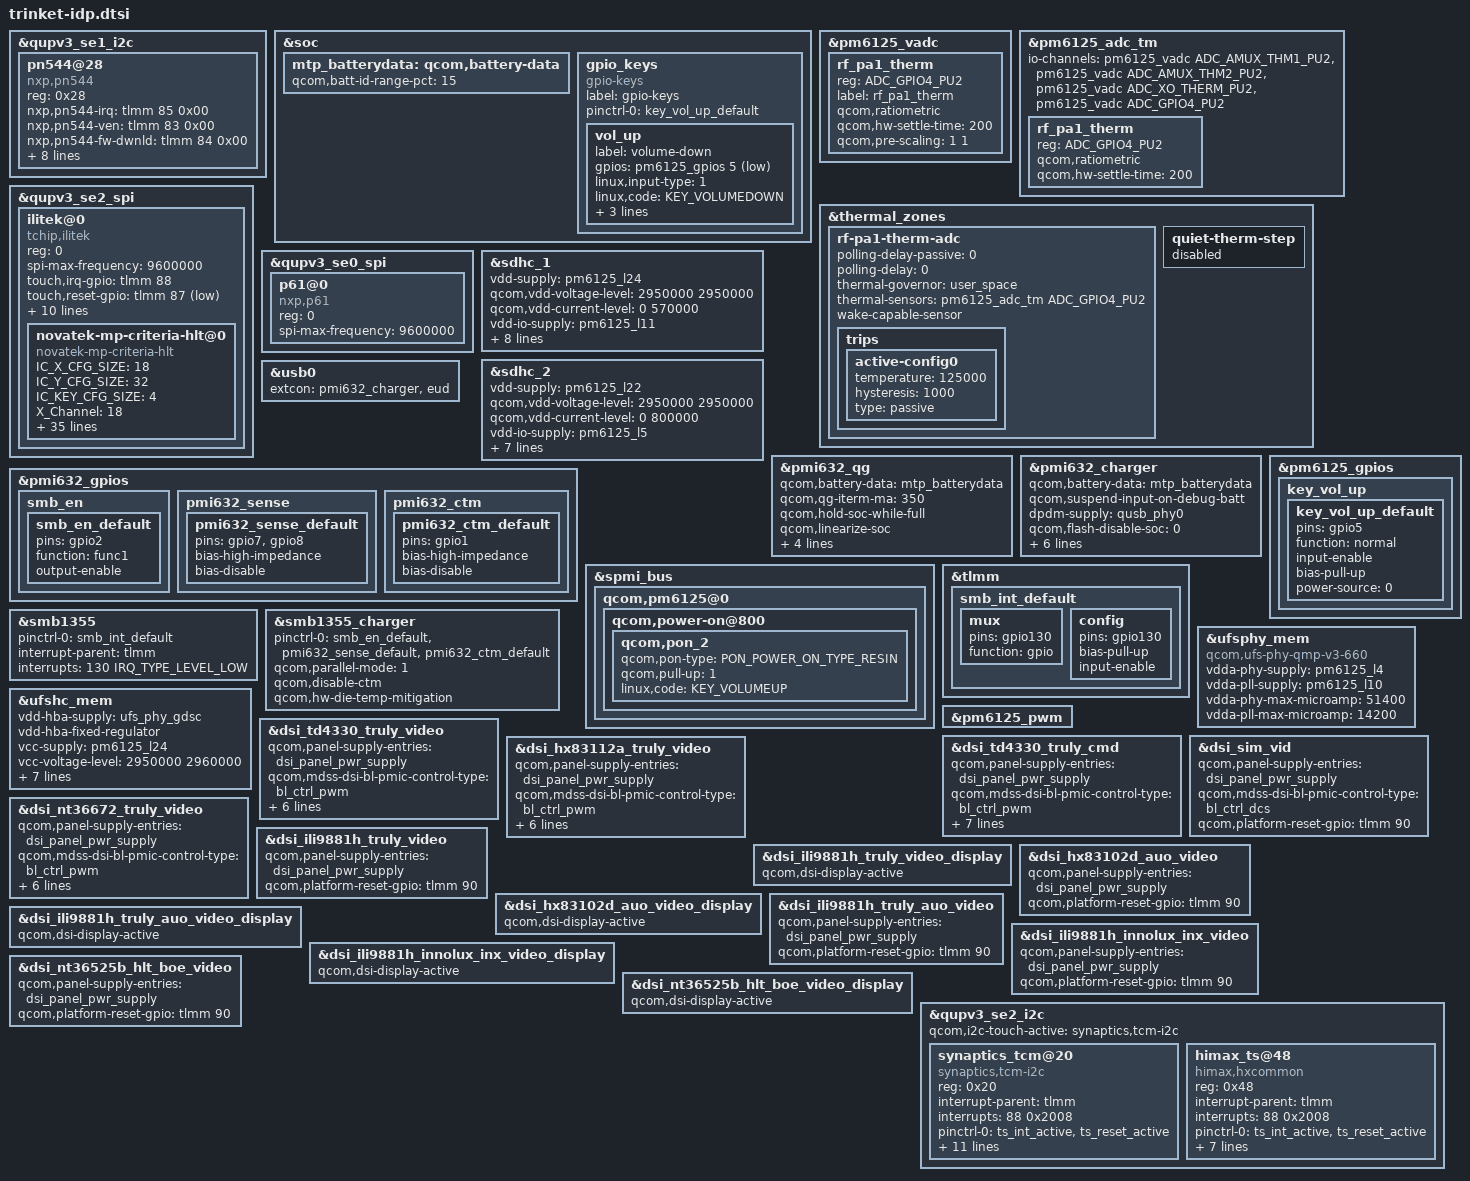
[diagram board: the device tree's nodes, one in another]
/*
 * Copyright (c) 2018-2019, The Linux Foundation. All rights reserved.
 *
 * This program is free software; you can redistribute it and/or modify
 * it under the terms of the GNU General Public License version 2 and
 * only version 2 as published by the Free Software Foundation.
 *
 * This program is distributed in the hope that it will be useful,
 * but WITHOUT ANY WARRANTY; without even the implied warranty of
 * MERCHANTABILITY or FITNESS FOR A PARTICULAR PURPOSE.  See the
 * GNU General Public License for more details.
 */
#include <dt-bindings/gpio/gpio.h>
#include <dt-bindings/input/input.h>
#include <dt-bindings/iio/qcom,spmi-vadc.h>
#include "trinket-thermal-overlay.dtsi"
#include "trinket-sde-display.dtsi"
#include <dt-bindings/clock/qcom,gcc-trinket.h>
#include "trinket-camera-sensor-idp.dtsi"
//Gong.Chen@ODM_WT.Bsp.Key.Function.1941873, 2019/04/10, Add for keyfunction
#include <dt-bindings/input/qcom,qpnp-power-on.h>

&qupv3_se1_i2c {
	status = "ok";
	#include "smb1355.dtsi"
};

&soc {
	mtp_batterydata: qcom,battery-data {
	//#ifndef ODM_WT_EDIT
	//Bin2.Zhang@ODM_WT.BSP.Charger.Basic.1941873, 20190416, Modify for battery temperature scale function
	//	qcom,batt-id-range-pct = <15>;
	//	#include "qg-batterydata-ascent-3450mah.dtsi"
	//	#include "qg-batterydata-mlp356477-2800mah.dtsi"
	//#else /* ODM_WT_EDIT */
		qcom,batt-id-range-pct = <15>;
		//#include "qg-batterydata-OPPO-DD003desay-ATL-4v4-4230mAh.dtsi"
		#include "qg-batterydata-OPPO-Brandon_ATL-4910mAh.dtsi"
	//#endif /* ODM_WT_EDIT */
	};

};

&pm6125_vadc {
	rf_pa1_therm {
		reg = <ADC_GPIO4_PU2>;
		label = "rf_pa1_therm";
		qcom,ratiometric;
		qcom,hw-settle-time = <200>;
		qcom,pre-scaling = <1 1>;
	};
};

&pm6125_adc_tm {
	io-channels = <&pm6125_vadc ADC_AMUX_THM1_PU2>,
			<&pm6125_vadc ADC_AMUX_THM2_PU2>,
			<&pm6125_vadc ADC_XO_THERM_PU2>,
			<&pm6125_vadc ADC_GPIO4_PU2>;

	rf_pa1_therm {
		reg = <ADC_GPIO4_PU2>;
		qcom,ratiometric;
		qcom,hw-settle-time = <200>;
	};
};

&thermal_zones {
	rf-pa1-therm-adc {
		polling-delay-passive = <0>;
		polling-delay = <0>;
		thermal-governor = "user_space";
		thermal-sensors = <&pm6125_adc_tm ADC_GPIO4_PU2>;
		wake-capable-sensor;
		trips {
			active-config0 {
				temperature = <125000>;
				hysteresis = <1000>;
				type = "passive";
			};
		};
	};

	quiet-therm-step {
		status = "disabled";
	};
};

&qupv3_se1_i2c {
	status = "ok";
/*Yuexiu.Wu@ODM_WT.WCN.NFC.Basic.1941873,2019/5/12,modify for use NXP NFC driver*/
	pn544@28 {
		compatible = "nxp,pn544";
		reg = <0x28>;
		nxp,pn544-irq = <&tlmm 85 0x00>;
		nxp,pn544-ven = <&tlmm 83 0x00>;
		nxp,pn544-fw-dwnld = <&tlmm 84 0x00>;
		nxp,pn544-clkreq = <&tlmm 95 0x00>;
		nxp,pn544-ese-pwr = <&tlmm 86 0x00>;
		interrupt-parent = <&tlmm>;
		interrupts = <85 0>;
		interrupt-names = "nfc_irq";
		pinctrl-names = "nfc_active", "nfc_suspend";
		pinctrl-0 = <&nfc_int_active &nfc_enable_active
				&nfc_clk_req_active>;
		pinctrl-1 = <&nfc_int_suspend &nfc_enable_suspend
				&nfc_clk_req_suspend>;
	};
};

&qupv3_se2_spi {
	status = "ok";
	ilitek@0 {
		compatible = "tchip,ilitek","novatek,NVT-ts-spi";
		reg = <0>; //Same as CS ID
		spi-max-frequency = <9600000>;	//4800000,9600000,15000000,19200000
		touch,irq-gpio = <&tlmm 88 0x00>;
		touch,reset-gpio = <&tlmm 87 0x2001>;
		pinctrl-names = "default", "suspend";
		pinctrl-0 = <&ts_int_active &ts_reset_active>;
		pinctrl-1 = <&ts_int_suspend &ts_reset_suspend>;
		vddio-supply = <&L9A>;
		lab-supply = <&lcdb_ldo_vreg>;
		ibb-supply = <&lcdb_ncp_vreg>;

		novatek,irq-gpio = <&tlmm 88 0>;
		novatek,reset-gpio = <&tlmm 87 0>;
		novatek,reset_global_gpio = <&tlmm 90 0>;
		/* 672A, 525B */
		novatek,swrst-n8-addr = <0x03F0FE>;
		status = "ok";

		/* MP */
		novatek,mp-support-dt;
		novatek-mp-criteria-hlt@0 {
			#address-cells = <1>;
			#size-cells = <0>;
			compatible = "novatek-mp-criteria-hlt";

			/* MP Config */
			IC_X_CFG_SIZE = <18>;
			IC_Y_CFG_SIZE = <32>;
			IC_KEY_CFG_SIZE = <4>;
			X_Channel = <18>;
			Y_Channel = <32>;
			AIN_X = <0 1 2 3 4 5 6 7 8 9 10 11 12 13 14 15 16 17>;
			AIN_Y = <0 1 2 3 4 5 6 7 8 9 10 11 12 13 14 15 16 17 18 19
								20 21 22 23 24 25 26 27 28 29 30 31>;
			AIN_KEY = <0 1 2 0xFF>;

			/* MP Criteria */
			PS_Config_Lmt_Short_Rawdata_P = <
				14008 14008 14008 14008 14008 14008 14008 14008 14008 14008 14008 14008 14008 14008 14008 14008 14008 14008
				14008 14008 14008 14008 14008 14008 14008 14008 14008 14008 14008 14008 14008 14008 14008 14008 14008 14008
				14008 14008 14008 14008 14008 14008 14008 14008 14008 14008 14008 14008 14008 14008 14008 14008 14008 14008
				14008 14008 14008 14008 14008 14008 14008 14008 14008 14008 14008 14008 14008 14008 14008 14008 14008 14008
				14008 14008 14008 14008 14008 14008 14008 14008 14008 14008 14008 14008 14008 14008 14008 14008 14008 14008
				14008 14008 14008 14008 14008 14008 14008 14008 14008 14008 14008 14008 14008 14008 14008 14008 14008 14008
				14008 14008 14008 14008 14008 14008 14008 14008 14008 14008 14008 14008 14008 14008 14008 14008 14008 14008
				14008 14008 14008 14008 14008 14008 14008 14008 14008 14008 14008 14008 14008 14008 14008 14008 14008 14008
				14008 14008 14008 14008 14008 14008 14008 14008 14008 14008 14008 14008 14008 14008 14008 14008 14008 14008
				14008 14008 14008 14008 14008 14008 14008 14008 14008 14008 14008 14008 14008 14008 14008 14008 14008 14008
				14008 14008 14008 14008 14008 14008 14008 14008 14008 14008 14008 14008 14008 14008 14008 14008 14008 14008
				14008 14008 14008 14008 14008 14008 14008 14008 14008 14008 14008 14008 14008 14008 14008 14008 14008 14008
				14008 14008 14008 14008 14008 14008 14008 14008 14008 14008 14008 14008 14008 14008 14008 14008 14008 14008
				14008 14008 14008 14008 14008 14008 14008 14008 14008 14008 14008 14008 14008 14008 14008 14008 14008 14008
				14008 14008 14008 14008 14008 14008 14008 14008 14008 14008 14008 14008 14008 14008 14008 14008 14008 14008
				14008 14008 14008 14008 14008 14008 14008 14008 14008 14008 14008 14008 14008 14008 14008 14008 14008 14008
				14008 14008 14008 14008 14008 14008 14008 14008 14008 14008 14008 14008 14008 14008 14008 14008 14008 14008
				14008 14008 14008 14008 14008 14008 14008 14008 14008 14008 14008 14008 14008 14008 14008 14008 14008 14008
				14008 14008 14008 14008 14008 14008 14008 14008 14008 14008 14008 14008 14008 14008 14008 14008 14008 14008
				14008 14008 14008 14008 14008 14008 14008 14008 14008 14008 14008 14008 14008 14008 14008 14008 14008 14008
				14008 14008 14008 14008 14008 14008 14008 14008 14008 14008 14008 14008 14008 14008 14008 14008 14008 14008
				14008 14008 14008 14008 14008 14008 14008 14008 14008 14008 14008 14008 14008 14008 14008 14008 14008 14008
				14008 14008 14008 14008 14008 14008 14008 14008 14008 14008 14008 14008 14008 14008 14008 14008 14008 14008
				14008 14008 14008 14008 14008 14008 14008 14008 14008 14008 14008 14008 14008 14008 14008 14008 14008 14008
				14008 14008 14008 14008 14008 14008 14008 14008 14008 14008 14008 14008 14008 14008 14008 14008 14008 14008
				14008 14008 14008 14008 14008 14008 14008 14008 14008 14008 14008 14008 14008 14008 14008 14008 14008 14008
				14008 14008 14008 14008 14008 14008 14008 14008 14008 14008 14008 14008 14008 14008 14008 14008 14008 14008
				14008 14008 14008 14008 14008 14008 14008 14008 14008 14008 14008 14008 14008 14008 14008 14008 14008 14008
				14008 14008 14008 14008 14008 14008 14008 14008 14008 14008 14008 14008 14008 14008 14008 14008 14008 14008
				14008 14008 14008 14008 14008 14008 14008 14008 14008 14008 14008 14008 14008 14008 14008 14008 14008 14008
				14008 14008 14008 14008 14008 14008 14008 14008 14008 14008 14008 14008 14008 14008 14008 14008 14008 14008
				14008 14008 14008 14008 14008 14008 14008 14008 14008 14008 14008 14008 14008 14008 14008 14008 14008 14008
				>;

			PS_Config_Lmt_Short_Rawdata_N = <
				11376 11376 11376 11376 11376 11376 11376 11376 11376 11376 11376 11376 11376 11376 11376 11376 11376 11376
				11376 11376 11376 11376 11376 11376 11376 11376 11376 11376 11376 11376 11376 11376 11376 11376 11376 11376
				11376 11376 11376 11376 11376 11376 11376 11376 11376 11376 11376 11376 11376 11376 11376 11376 11376 11376
				11376 11376 11376 11376 11376 11376 11376 11376 11376 11376 11376 11376 11376 11376 11376 11376 11376 11376
				11376 11376 11376 11376 11376 11376 11376 11376 11376 11376 11376 11376 11376 11376 11376 11376 11376 11376
				11376 11376 11376 11376 11376 11376 11376 11376 11376 11376 11376 11376 11376 11376 11376 11376 11376 11376
				11376 11376 11376 11376 11376 11376 11376 11376 11376 11376 11376 11376 11376 11376 11376 11376 11376 11376
				11376 11376 11376 11376 11376 11376 11376 11376 11376 11376 11376 11376 11376 11376 11376 11376 11376 11376
				11376 11376 11376 11376 11376 11376 11376 11376 11376 11376 11376 11376 11376 11376 11376 11376 11376 11376
				11376 11376 11376 11376 11376 11376 11376 11376 11376 11376 11376 11376 11376 11376 11376 11376 11376 11376
				11376 11376 11376 11376 11376 11376 11376 11376 11376 11376 11376 11376 11376 11376 11376 11376 11376 11376
				11376 11376 11376 11376 11376 11376 11376 11376 11376 11376 11376 11376 11376 11376 11376 11376 11376 11376
				11376 11376 11376 11376 11376 11376 11376 11376 11376 11376 11376 11376 11376 11376 11376 11376 11376 11376
				11376 11376 11376 11376 11376 11376 11376 11376 11376 11376 11376 11376 11376 11376 11376 11376 11376 11376
				11376 11376 11376 11376 11376 11376 11376 11376 11376 11376 11376 11376 11376 11376 11376 11376 11376 11376
				11376 11376 11376 11376 11376 11376 11376 11376 11376 11376 11376 11376 11376 11376 11376 11376 11376 11376
				11376 11376 11376 11376 11376 11376 11376 11376 11376 11376 11376 11376 11376 11376 11376 11376 11376 11376
				11376 11376 11376 11376 11376 11376 11376 11376 11376 11376 11376 11376 11376 11376 11376 11376 11376 11376
				11376 11376 11376 11376 11376 11376 11376 11376 11376 11376 11376 11376 11376 11376 11376 11376 11376 11376
				11376 11376 11376 11376 11376 11376 11376 11376 11376 11376 11376 11376 11376 11376 11376 11376 11376 11376
				11376 11376 11376 11376 11376 11376 11376 11376 11376 11376 11376 11376 11376 11376 11376 11376 11376 11376
				11376 11376 11376 11376 11376 11376 11376 11376 11376 11376 11376 11376 11376 11376 11376 11376 11376 11376
				11376 11376 11376 11376 11376 11376 11376 11376 11376 11376 11376 11376 11376 11376 11376 11376 11376 11376
				11376 11376 11376 11376 11376 11376 11376 11376 11376 11376 11376 11376 11376 11376 11376 11376 11376 11376
				11376 11376 11376 11376 11376 11376 11376 11376 11376 11376 11376 11376 11376 11376 11376 11376 11376 11376
				11376 11376 11376 11376 11376 11376 11376 11376 11376 11376 11376 11376 11376 11376 11376 11376 11376 11376
				11376 11376 11376 11376 11376 11376 11376 11376 11376 11376 11376 11376 11376 11376 11376 11376 11376 11376
				11376 11376 11376 11376 11376 11376 11376 11376 11376 11376 11376 11376 11376 11376 11376 11376 11376 11376
				11376 11376 11376 11376 11376 11376 11376 11376 11376 11376 11376 11376 11376 11376 11376 11376 11376 11376
				11376 11376 11376 11376 11376 11376 11376 11376 11376 11376 11376 11376 11376 11376 11376 11376 11376 11376
				11376 11376 11376 11376 11376 11376 11376 11376 11376 11376 11376 11376 11376 11376 11376 11376 11376 11376
				11376 11376 11376 11376 11376 11376 11376 11376 11376 11376 11376 11376 11376 11376 11376 11376 11376 11376
				>;

			PS_Config_Lmt_Open_Rawdata_P = <
				3120	3133	3130	3154	3185	3147	3129	3200	65535 65535 3103	3036	3067	3108	3151	3206	3227	3165
				2879	2899	2934	2996	3052	3040	3025	3008	2954	2910	2984	2998	3025	3039	3059	3075	3052	2982
				2961	2980	3017	3085	3151	3143	3122	3108	3033	2924	3005	3028	3049	3064	3080	3103	3078	3024
				2973	2980	3015	3085	3155	3148	3130	3115	3039	2969	3056	3077	3099	3116	3131	3154	3136	3087
				3000	3011	3045	3117	3189	3179	3158	3145	3063	2951	3038	3061	3082	3103	3116	3138	3124	3080
				2986	2993	3028	3101	3175	3183	3162	3150	3063	3011	3108	3130	3152	3173	3185	3207	3201	3155
				3082	3105	3133	3138	3136	3123	3126	3109	3067	3186	3218	3245	3241	3232	3148	3061	2997	2940
				3123	3143	3176	3183	3175	3169	3158	3148	3105	3218	3253	3271	3281	3283	3203	3113	3046	2990
				3126	3145	3185	3194	3185	3182	3161	3157	3109	3225	3263	3278	3298	3298	3220	3127	3064	3008
				3171	3189	3236	3242	3236	3234	3217	3200	3152	3276	3316	3341	3360	3367	3281	3193	3127	3071
				3208	3222	3271	3277	3264	3259	3239	3222	3183	3281	3318	3343	3365	3374	3306	3218	3151	3096
				3249	3263	3318	3326	3318	3311	3280	3264	3228	3327	3365	3389	3424	3432	3364	3271	3204	3148
				3246	3257	3339	3341	3337	3323	3298	3284	3253	3336	3371	3392	3425	3438	3372	3288	3206	3144
				3271	3297	3368	3382	3364	3357	3330	3318	3287	3382	3417	3438	3472	3481	3432	3348	3266	3201
				3313	3339	3407	3417	3403	3385	3368	3358	3320	3389	3431	3453	3473	3501	3451	3376	3294	3229
				3355	3386	3452	3472	3449	3439	3413	3402	3358	3446	3490	3515	3544	3561	3526	3448	3364	3297
				3371	3399	3467	3479	3467	3456	3434	3420	3376	3437	3483	3508	3536	3554	3521	3456	3372	3306
				3414	3444	3505	3518	3507	3494	3469	3456	3409	3469	3518	3544	3571	3592	3563	3501	3424	3357
				3445	3466	3532	3532	3530	3521	3501	3480	3434	3487	3547	3570	3603	3617	3595	3540	3472	3397
				3491	3516	3577	3588	3577	3563	3543	3521	3470	3515	3575	3600	3631	3649	3640	3582	3514	3438
				3508	3523	3584	3600	3588	3575	3557	3535	3483	3516	3582	3605	3637	3652	3649	3588	3526	3458
				3546	3557	3619	3641	3627	3614	3596	3574	3518	3553	3620	3644	3676	3691	3698	3642	3575	3509
				3592	3609	3654	3711	3708	3694	3672	3654	3591	3556	3628	3649	3682	3697	3719	3693	3642	3578
				3606	3621	3662	3712	3715	3701	3680	3663	3596	3616	3691	3715	3747	3761	3782	3770	3718	3655
				3651	3656	3697	3743	3752	3738	3719	3698	3634	3582	3655	3680	3707	3724	3743	3738	3690	3634
				3661	3663	3701	3743	3754	3742	3725	3705	3638	3638	3717	3742	3767	3785	3806	3808	3763	3708
				3516	3724	3752	3796	3809	3798	3802	3785	3717	3666	3743	3767	3768	3789	3806	3809	3774	3511
				3511	3722	3756	3787	3802	3789	3795	3775	3705	3712	3794	3817	3822	3840	3858	3876	3841	3564
				3554	3773	3799	3831	3847	3836	3837	3823	3747	3686	3770	3789	3796	3816	3834	3852	3826	3546
				3536	3756	3784	3809	3827	3817	3819	3805	3728	3739	3824	3845	3852	3872	3892	3920	3892	3603
				3599	3823	3845	3865	3883	3872	3875	3861	3785	3726	3813	3834	3843	3861	3879	3908	3890	3600
				3683	3743	3840	3859	3878	3865	3868	3852	3774	3771	3865	3887	3894	3914	3934	3962	3864	3747
				>;

			PS_Config_Lmt_Open_Rawdata_N = <
				1337	1342	1341	1351	1365	1348	1341	1371	(-65535) (-65535) 1330 1301 1314 1332 1350 1374 1383 1356
				1234	1242	1257	1284	1308	1303	1296	1289	1266	1247	1279	1285	1296	1302	1311	1318	1308	1278
				1269	1277	1293	1322	1350	1347	1338	1332	1300	1253	1288	1297	1306	1313	1320	1330	1319	1296
				1274	1277	1292	1322	1352	1349	1341	1335	1302	1272	1309	1318	1328	1335	1342	1351	1344	1323
				1285	1290	1305	1336	1366	1362	1353	1348	1312	1264	1302	1312	1321	1330	1335	1345	1339	1320
				1279	1282	1297	1329	1360	1364	1355	1350	1312	1290	1332	1341	1351	1360	1365	1374	1372	1352
				1321	1330	1342	1345	1344	1338	1339	1332	1314	1365	1379	1390	1389	1385	1349	1312	1284	1260
				1338	1347	1361	1364	1360	1358	1353	1349	1330	1379	1394	1402	1406	1407	1372	1334	1305	1281
				1339	1348	1365	1369	1365	1363	1354	1353	1332	1382	1398	1405	1413	1413	1380	1340	1313	1289
				1359	1366	1387	1389	1387	1386	1378	1371	1351	1404	1421	1432	1440	1443	1406	1368	1340	1316
				1375	1381	1402	1404	1399	1396	1388	1381	1364	1406	1422	1432	1442	1446	1417	1379	1350	1327
				1392	1398	1422	1425	1422	1419	1405	1399	1383	1426	1442	1452	1467	1471	1441	1402	1373	1349
				1391	1396	1431	1432	1430	1424	1413	1407	1394	1429	1444	1453	1468	1473	1445	1409	1374	1347
				1402	1413	1443	1449	1441	1438	1427	1422	1408	1449	1464	1473	1488	1492	1471	1435	1399	1372
				1420	1431	1460	1464	1458	1450	1443	1439	1423	1452	1470	1480	1488	1500	1479	1447	1411	1384
				1438	1451	1479	1488	1478	1474	1462	1458	1439	1477	1495	1506	1519	1526	1511	1477	1441	1413
				1444	1456	1486	1491	1486	1481	1471	1465	1447	1473	1492	1503	1515	1523	1509	1481	1445	1417
				1463	1476	1502	1507	1503	1497	1486	1481	1461	1486	1507	1519	1530	1539	1527	1500	1467	1438
				1476	1485	1513	1513	1513	1509	1500	1491	1471	1494	1520	1530	1544	1550	1540	1517	1488	1456
				1496	1507	1533	1537	1533	1527	1518	1509	1487	1506	1532	1543	1556	1564	1560	1535	1506	1473
				1503	1510	1536	1543	1537	1532	1524	1515	1492	1507	1535	1545	1558	1565	1564	1537	1511	1482
				1519	1524	1551	1560	1554	1549	1541	1531	1507	1522	1551	1561	1575	1582	1585	1561	1532	1504
				1539	1546	1566	1590	1589	1583	1573	1566	1539	1524	1555	1564	1578	1584	1594	1582	1561	1533
				1545	1552	1569	1591	1592	1586	1577	1570	1541	1549	1582	1592	1606	1612	1621	1615	1593	1566
				1564	1567	1584	1604	1608	1602	1594	1585	1557	1535	1566	1577	1588	1596	1604	1602	1581	1557
				1569	1570	1586	1604	1609	1603	1596	1588	1559	1559	1593	1603	1614	1622	1631	1632	1612	1589
				1507	1596	1608	1627	1632	1627	1629	1622	1593	1571	1604	1614	1615	1624	1631	1632	1617	1504
				1504	1595	1609	1623	1629	1624	1626	1618	1588	1591	1626	1636	1638	1645	1653	1661	1646	1527
				1523	1617	1628	1642	1648	1644	1644	1638	1606	1579	1615	1624	1627	1635	1643	1651	1639	1519
				1515	1609	1621	1632	1640	1636	1636	1630	1597	1602	1639	1648	1651	1659	1668	1680	1668	1544
				1542	1638	1648	1656	1664	1659	1660	1654	1622	1597	1634	1643	1647	1654	1662	1675	1667	1543
				1578	1604	1645	1654	1662	1656	1657	1651	1617	1616	1656	1666	1669	1677	1686	1698	1656	1606
				>;

			PS_Config_Lmt_FW_Rawdata_P = <
				1677	1682	1684	1675	1678	1675	1674	1674	65535 65535 1674 1675 1681 1681 1684 1684 1685 1682
				1675	1680	1678	1681	1678	1677	1678	1674	1671	1677	1681	1684	1688	1681	1681	1687	1675	1687
				1674	1687	1682	1681	1685	1681	1682	1687	1681	1678	1684	1681	1680	1685	1678	1678	1674	1684
				1689	1670	1680	1666	1668	1664	1667	1668	1677	1680	1680	1675	1684	1684	1685	1685	1681	1685
				1674	1696	1687	1681	1674	1673	1673	1684	1684	1687	1680	1682	1685	1680	1684	1691	1670	1689
				1684	1681	1682	1673	1671	1670	1667	1667	1691	1681	1673	1673	1681	1688	1691	1678	1680	1674
				1678	1681	1678	1681	1684	1689	1688	1675	1687	1684	1678	1682	1682	1681	1680	1678	1671	1685
				1678	1678	1667	1671	1681	1685	1678	1674	1684	1674	1677	1673	1674	1675	1689	1684	1685	1688
				1678	1689	1682	1682	1691	1689	1687	1687	1682	1671	1684	1685	1685	1677	1680	1680	1687	1687
				1685	1682	1689	1691	1682	1682	1682	1682	1685	1678	1671	1674	1678	1664	1682	1681	1678	1684
				1677	1677	1674	1668	1680	1675	1684	1670	1670	1682	1682	1687	1675	1675	1680	1687	1694	1680
				1681	1689	1675	1684	1682	1687	1675	1680	1680	1682	1671	1677	1675	1680	1677	1674	1677	1671
				1674	1678	1677	1687	1680	1673	1680	1687	1675	1681	1691	1695	1694	1681	1680	1678	1684	1678
				1673	1680	1681	1680	1682	1678	1682	1692	1685	1671	1673	1675	1684	1667	1674	1675	1687	1681
				1682	1698	1680	1675	1687	1684	1685	1687	1681	1678	1680	1681	1671	1682	1692	1675	1689	1682
				1677	1682	1678	1682	1685	1681	1684	1680	1680	1684	1682	1681	1685	1673	1684	1687	1673	1678
				1673	1681	1677	1688	1682	1674	1673	1673	1661	1680	1675	1673	1673	1667	1661	1685	1668	1668
				1684	1691	1667	1667	1667	1670	1670	1674	1680	1674	1680	1684	1680	1678	1681	1689	1678	1677
				1689	1694	1689	1691	1689	1680	1684	1687	1688	1675	1680	1687	1687	1677	1675	1677	1685	1678
				1688	1692	1688	1684	1681	1680	1681	1677	1674	1675	1675	1682	1678	1685	1688	1681	1684	1691
				1674	1677	1685	1671	1691	1688	1681	1692	1671	1687	1685	1682	1684	1678	1674	1678	1685	1680
				1684	1687	1682	1692	1677	1673	1670	1675	1684	1681	1681	1685	1688	1682	1682	1684	1685	1687
				1677	1674	1682	1673	1681	1694	1694	1674	1674	1684	1675	1678	1677	1680	1680	1678	1688	1675
				1687	1675	1680	1680	1681	1678	1678	1685	1684	1673	1685	1688	1688	1681	1691	1689	1682	1684
				1680	1687	1675	1673	1678	1678	1674	1671	1671	1687	1681	1677	1677	1673	1673	1680	1678	1681
				1671	1681	1688	1680	1677	1674	1678	1682	1691	1673	1682	1680	1678	1687	1674	1675	1677	1677
				1684	1673	1687	1685	1685	1681	1688	1681	1681	1680	1680	1684	1678	1684	1685	1687	1689	1670
				1698	1685	1685	1685	1675	1675	1674	1684	1670	1682	1685	1689	1689	1667	1680	1673	1688	1688
				1675	1680	1675	1671	1673	1684	1681	1681	1682	1677	1688	1687	1678	1684	1687	1675	1681	1675
				1687	1668	1674	1674	1681	1687	1674	1663	1677	1681	1682	1687	1681	1677	1675	1674	1691	1687
				1674	1674	1678	1680	1677	1681	1673	1668	1681	1695	1684	1680	1680	1675	1671	1678	1685	1689
				1675	1695	1684	1674	1680	1675	1684	1688	1677	1680	1685	1674	1678	1673	1680	1681	1671	1673
				>;

			PS_Config_Lmt_FW_Rawdata_N = <
				718 721 721 718 719 718 717 717 (-65535) (-65535) 717 718 720 720 721 721 722 721
				718 720 719 720 719 718 719 717 716 718 720 721 723 720 720 723 718 723
				717 723 721 720 722 720 721 723 720 719 721 720 720 722 719 719 717 721
				724 715 720 714 715 713 714 715 718 720 720 718 721 721 722 722 720 722
				717 727 723 720 717 717 717 721 721 723 720 721 722 720 721 724 715 724
				721 720 721 717 716 715 714 714 724 720 717 717 720 723 724 719 720 717
				719 720 719 720 721 724 723 718 723 721 719 721 721 720 720 719 716 722
				719 719 714 716 720 722 719 717 721 717 718 717 717 718 724 721 722 723
				719 724 721 721 724 724 723 723 721 716 721 722 722 718 720 720 723 723
				722 721 724 724 721 721 721 721 722 719 716 717 719 713 721 720 719 721
				718 718 717 715 720 718 721 715 715 721 721 723 718 718 720 723 726 720
				720 724 718 721 721 723 718 720 720 721 716 718 718 720 718 717 718 716
				717 719 718 723 720 717 720 723 718 720 724 726 726 720 720 719 721 719
				717 720 720 720 721 719 721 725 722 716 717 718 721 714 717 718 723 720
				721 727 720 718 723 721 722 723 720 719 720 720 716 721 725 718 724 721
				718 721 719 721 722 720 721 720 720 721 721 720 722 717 721 723 717 719
				717 720 718 723 721 717 717 717 712 720 718 717 717 714 712 722 715 715
				721 724 714 714 714 715 715 717 720 717 720 721 720 719 720 724 719 718
				724 726 724 724 724 720 721 723 723 718 720 723 723 718 718 718 722 719
				723 725 723 721 720 720 720 718 717 718 718 721 719 722 723 720 721 724
				717 718 722 716 724 723 720 725 716 723 722 721 721 719 717 719 722 720
				721 723 721 725 718 717 715 718 721 720 720 722 723 721 721 721 722 723
				718 717 721 717 720 726 726 717 717 721 718 719 718 720 720 719 723 718
				723 718 720 720 720 719 719 722 721 717 722 723 723 720 724 724 721 721
				720 723 718 717 719 719 717 716 716 723 720 718 718 717 717 720 719 720
				716 720 723 720 718 717 719 721 724 717 721 720 719 723 717 718 718 718
				721 717 723 722 722 720 723 720 720 720 720 721 719 721 722 723 724 715
				727 722 722 722 718 718 717 721 715 721 722 724 724 714 720 717 723 723
				718 720 718 716 717 721 720 720 721 718 723 723 719 721 723 718 720 718
				723 715 717 717 720 723 717 712 718 720 721 723 720 718 718 717 724 723
				717 717 719 720 718 720 717 715 720 726 721 720 720 718 716 719 722 724
				718 726 721 717 720 718 721 723 718 720 722 717 719 717 720 720 716 717
				>;

			PS_Config_Lmt_FW_CC_P = <
				100 99 99 100 100 100 102 102 65535 65535 103 103 102 102 102 102 102 102
				103 100 100 100 100 100 100 100 103 107 104 104 104 104 104 104 106 107
				104 102 102 102 102 102 102 102 106 107 103 103 103 103 103 104 104 107
				103 102 100 102 102 102 102 102 104 109 106 106 106 106 106 106 107 109
				104 103 102 103 103 103 103 103 107 107 104 104 104 104 104 104 106 107
				104 102 102 102 103 103 103 103 107 110 107 107 107 106 106 106 107 110
				106 104 103 103 103 103 103 103 107 111 107 107 107 107 106 106 106 109
				109 106 106 106 106 104 106 106 109 113 110 110 110 109 109 109 109 110
				106 104 104 104 103 103 103 104 107 111 107 107 107 107 107 106 106 109
				109 106 106 106 106 106 106 106 109 113 110 110 110 110 109 109 109 111
				107 104 104 104 103 103 104 104 107 110 107 107 107 107 107 106 106 109
				109 106 106 106 106 106 106 106 109 113 110 110 110 110 110 109 109 111
				107 104 104 104 103 103 103 104 107 111 107 107 107 107 107 106 106 109
				109 106 106 106 106 106 106 106 110 114 110 110 110 110 110 109 110 111
				107 104 104 104 103 103 103 104 107 110 107 107 107 107 107 106 107 109
				109 106 106 106 106 106 106 106 109 113 110 110 110 110 109 109 109 111
				107 104 104 104 104 103 104 104 107 111 107 107 107 107 107 107 107 110
				109 107 106 107 106 106 106 106 110 113 110 110 110 110 110 110 110 113
				107 104 104 104 103 103 103 104 107 111 107 107 107 107 107 107 107 110
				110 107 106 106 106 106 106 106 109 113 110 110 110 110 110 110 110 113
				109 106 104 106 104 104 104 104 107 111 107 107 107 107 107 107 109 110
				110 107 107 107 107 106 107 107 110 113 110 110 110 110 110 110 110 113
				107 106 104 104 104 104 104 104 107 109 106 106 106 106 106 106 107 109
				106 103 103 103 103 103 103 103 106 111 107 107 107 107 107 107 109 111
				107 106 104 104 104 104 104 104 107 110 107 107 106 106 106 106 107 110
				107 104 103 103 103 103 103 103 106 111 109 109 109 107 109 109 109 111
				106 106 104 104 104 104 104 104 107 110 106 106 106 106 106 106 107 107
				104 103 103 103 103 103 103 103 106 111 109 109 109 107 107 109 109 109
				106 106 104 104 104 104 104 104 107 110 107 107 107 106 106 106 107 107
				104 104 103 103 103 103 103 103 107 111 109 109 109 109 109 109 109 110
				106 106 104 104 104 104 104 104 109 110 107 107 107 106 106 106 107 107
				104 103 103 103 103 103 103 103 107 113 109 109 109 107 107 109 109 110
				>;

			PS_Config_Lmt_FW_CC_N = <
				45 44 44 45 45 45 45 45 (-65535) (-65535) 46 46 45 45 45 45 45 45
				46 45 45 45 45 45 45 45 46 48 47 47 47 47 47 47 47 48
				47 45 45 45 45 45 45 45 47 48 46 46 46 46 46 47 47 48
				46 45 45 45 45 45 45 45 47 48 47 47 47 47 47 47 48 48
				47 46 45 46 46 46 46 46 48 48 47 47 47 47 47 47 47 48
				47 45 45 45 46 46 46 46 48 49 48 48 48 47 47 47 48 49
				47 47 46 46 46 46 46 46 48 50 48 48 48 48 47 47 47 48
				48 47 47 47 47 47 47 47 48 50 49 49 49 48 48 48 48 49
				47 47 47 47 46 46 46 47 48 50 48 48 48 48 48 47 47 48
				48 47 47 47 47 47 47 47 48 50 49 49 49 49 48 48 48 50
				48 47 47 47 46 46 47 47 48 49 48 48 48 48 48 47 47 48
				48 47 47 47 47 47 47 47 48 50 49 49 49 49 49 48 48 50
				48 47 47 47 46 46 46 47 48 50 48 48 48 48 48 47 47 48
				48 47 47 47 47 47 47 47 49 51 49 49 49 49 49 48 49 50
				48 47 47 47 46 46 46 47 48 49 48 48 48 48 48 47 48 48
				48 47 47 47 47 47 47 47 48 50 49 49 49 49 48 48 48 50
				48 47 47 47 47 46 47 47 48 50 48 48 48 48 48 48 48 49
				48 48 47 48 47 47 47 47 49 50 49 49 49 49 49 49 49 50
				48 47 47 47 46 46 46 47 48 50 48 48 48 48 48 48 48 49
				49 48 47 47 47 47 47 47 48 50 49 49 49 49 49 49 49 50
				48 47 47 47 47 47 47 47 48 50 48 48 48 48 48 48 48 49
				49 48 48 48 48 47 48 48 49 50 49 49 49 49 49 49 49 50
				48 47 47 47 47 47 47 47 48 48 47 47 47 47 47 47 48 48
				47 46 46 46 46 46 46 46 47 50 48 48 48 48 48 48 48 50
				48 47 47 47 47 47 47 47 48 49 48 48 47 47 47 47 48 49
				48 47 46 46 46 46 46 46 47 50 48 48 48 48 48 48 48 50
				47 47 47 47 47 47 47 47 48 49 47 47 47 47 47 47 48 48
				47 46 46 46 46 46 46 46 47 50 48 48 48 48 48 48 48 48
				47 47 47 47 47 47 47 47 48 49 48 48 48 47 47 47 48 48
				47 47 46 46 46 46 46 46 48 50 48 48 48 48 48 48 48 49
				47 47 47 47 47 47 47 47 48 49 48 48 48 47 47 47 48 48
				47 46 46 46 46 46 46 46 48 50 48 48 48 48 48 48 48 49
				>;

			PS_Config_Lmt_FW_Diff_P = <
				50 50 50 50 50 50 50 50 65535 65535 50 50 50 50 50 50 50 50
				50 50 50 50 50 50 50 50 50 50 50 50 50 50 50 50 50 50
				50 50 50 50 50 50 50 50 50 50 50 50 50 50 50 50 50 50
				50 50 50 50 50 50 50 50 50 50 50 50 50 50 50 50 50 50
				50 50 50 50 50 50 50 50 50 50 50 50 50 50 50 50 50 50
				50 50 50 50 50 50 50 50 50 50 50 50 50 50 50 50 50 50
				50 50 50 50 50 50 50 50 50 50 50 50 50 50 50 50 50 50
				50 50 50 50 50 50 50 50 50 50 50 50 50 50 50 50 50 50
				50 50 50 50 50 50 50 50 50 50 50 50 50 50 50 50 50 50
				50 50 50 50 50 50 50 50 50 50 50 50 50 50 50 50 50 50
				50 50 50 50 50 50 50 50 50 50 50 50 50 50 50 50 50 50
				50 50 50 50 50 50 50 50 50 50 50 50 50 50 50 50 50 50
				50 50 50 50 50 50 50 50 50 50 50 50 50 50 50 50 50 50
				50 50 50 50 50 50 50 50 50 50 50 50 50 50 50 50 50 50
				50 50 50 50 50 50 50 50 50 50 50 50 50 50 50 50 50 50
				50 50 50 50 50 50 50 50 50 50 50 50 50 50 50 50 50 50
				50 50 50 50 50 50 50 50 50 50 50 50 50 50 50 50 50 50
				50 50 50 50 50 50 50 50 50 50 50 50 50 50 50 50 50 50
				50 50 50 50 50 50 50 50 50 50 50 50 50 50 50 50 50 50
				50 50 50 50 50 50 50 50 50 50 50 50 50 50 50 50 50 50
				50 50 50 50 50 50 50 50 50 50 50 50 50 50 50 50 50 50
				50 50 50 50 50 50 50 50 50 50 50 50 50 50 50 50 50 50
				50 50 50 50 50 50 50 50 50 50 50 50 50 50 50 50 50 50
				50 50 50 50 50 50 50 50 50 50 50 50 50 50 50 50 50 50
				50 50 50 50 50 50 50 50 50 50 50 50 50 50 50 50 50 50
				50 50 50 50 50 50 50 50 50 50 50 50 50 50 50 50 50 50
				50 50 50 50 50 50 50 50 50 50 50 50 50 50 50 50 50 50
				50 50 50 50 50 50 50 50 50 50 50 50 50 50 50 50 50 50
				50 50 50 50 50 50 50 50 50 50 50 50 50 50 50 50 50 50
				50 50 50 50 50 50 50 50 50 50 50 50 50 50 50 50 50 50
				50 50 50 50 50 50 50 50 50 50 50 50 50 50 50 50 50 50
				50 50 50 50 50 50 50 50 50 50 50 50 50 50 50 50 50 50
				>;

			PS_Config_Lmt_FW_Diff_N = <
				(-50) (-50) (-50) (-50) (-50) (-50) (-50) (-50) (-65535) (-65535) (-50) (-50) (-50) (-50) (-50) (-50) (-50) (-50)
				(-50) (-50) (-50) (-50) (-50) (-50) (-50) (-50) (-50) (-50) (-50) (-50) (-50) (-50) (-50) (-50) (-50) (-50)
				(-50) (-50) (-50) (-50) (-50) (-50) (-50) (-50) (-50) (-50) (-50) (-50) (-50) (-50) (-50) (-50) (-50) (-50)
				(-50) (-50) (-50) (-50) (-50) (-50) (-50) (-50) (-50) (-50) (-50) (-50) (-50) (-50) (-50) (-50) (-50) (-50)
				(-50) (-50) (-50) (-50) (-50) (-50) (-50) (-50) (-50) (-50) (-50) (-50) (-50) (-50) (-50) (-50) (-50) (-50)
				(-50) (-50) (-50) (-50) (-50) (-50) (-50) (-50) (-50) (-50) (-50) (-50) (-50) (-50) (-50) (-50) (-50) (-50)
				(-50) (-50) (-50) (-50) (-50) (-50) (-50) (-50) (-50) (-50) (-50) (-50) (-50) (-50) (-50) (-50) (-50) (-50)
				(-50) (-50) (-50) (-50) (-50) (-50) (-50) (-50) (-50) (-50) (-50) (-50) (-50) (-50) (-50) (-50) (-50) (-50)
				(-50) (-50) (-50) (-50) (-50) (-50) (-50) (-50) (-50) (-50) (-50) (-50) (-50) (-50) (-50) (-50) (-50) (-50)
				(-50) (-50) (-50) (-50) (-50) (-50) (-50) (-50) (-50) (-50) (-50) (-50) (-50) (-50) (-50) (-50) (-50) (-50)
				(-50) (-50) (-50) (-50) (-50) (-50) (-50) (-50) (-50) (-50) (-50) (-50) (-50) (-50) (-50) (-50) (-50) (-50)
				(-50) (-50) (-50) (-50) (-50) (-50) (-50) (-50) (-50) (-50) (-50) (-50) (-50) (-50) (-50) (-50) (-50) (-50)
				(-50) (-50) (-50) (-50) (-50) (-50) (-50) (-50) (-50) (-50) (-50) (-50) (-50) (-50) (-50) (-50) (-50) (-50)
				(-50) (-50) (-50) (-50) (-50) (-50) (-50) (-50) (-50) (-50) (-50) (-50) (-50) (-50) (-50) (-50) (-50) (-50)
				(-50) (-50) (-50) (-50) (-50) (-50) (-50) (-50) (-50) (-50) (-50) (-50) (-50) (-50) (-50) (-50) (-50) (-50)
				(-50) (-50) (-50) (-50) (-50) (-50) (-50) (-50) (-50) (-50) (-50) (-50) (-50) (-50) (-50) (-50) (-50) (-50)
				(-50) (-50) (-50) (-50) (-50) (-50) (-50) (-50) (-50) (-50) (-50) (-50) (-50) (-50) (-50) (-50) (-50) (-50)
				(-50) (-50) (-50) (-50) (-50) (-50) (-50) (-50) (-50) (-50) (-50) (-50) (-50) (-50) (-50) (-50) (-50) (-50)
				(-50) (-50) (-50) (-50) (-50) (-50) (-50) (-50) (-50) (-50) (-50) (-50) (-50) (-50) (-50) (-50) (-50) (-50)
				(-50) (-50) (-50) (-50) (-50) (-50) (-50) (-50) (-50) (-50) (-50) (-50) (-50) (-50) (-50) (-50) (-50) (-50)
				(-50) (-50) (-50) (-50) (-50) (-50) (-50) (-50) (-50) (-50) (-50) (-50) (-50) (-50) (-50) (-50) (-50) (-50)
				(-50) (-50) (-50) (-50) (-50) (-50) (-50) (-50) (-50) (-50) (-50) (-50) (-50) (-50) (-50) (-50) (-50) (-50)
				(-50) (-50) (-50) (-50) (-50) (-50) (-50) (-50) (-50) (-50) (-50) (-50) (-50) (-50) (-50) (-50) (-50) (-50)
				(-50) (-50) (-50) (-50) (-50) (-50) (-50) (-50) (-50) (-50) (-50) (-50) (-50) (-50) (-50) (-50) (-50) (-50)
				(-50) (-50) (-50) (-50) (-50) (-50) (-50) (-50) (-50) (-50) (-50) (-50) (-50) (-50) (-50) (-50) (-50) (-50)
				(-50) (-50) (-50) (-50) (-50) (-50) (-50) (-50) (-50) (-50) (-50) (-50) (-50) (-50) (-50) (-50) (-50) (-50)
				(-50) (-50) (-50) (-50) (-50) (-50) (-50) (-50) (-50) (-50) (-50) (-50) (-50) (-50) (-50) (-50) (-50) (-50)
				(-50) (-50) (-50) (-50) (-50) (-50) (-50) (-50) (-50) (-50) (-50) (-50) (-50) (-50) (-50) (-50) (-50) (-50)
				(-50) (-50) (-50) (-50) (-50) (-50) (-50) (-50) (-50) (-50) (-50) (-50) (-50) (-50) (-50) (-50) (-50) (-50)
				(-50) (-50) (-50) (-50) (-50) (-50) (-50) (-50) (-50) (-50) (-50) (-50) (-50) (-50) (-50) (-50) (-50) (-50)
				(-50) (-50) (-50) (-50) (-50) (-50) (-50) (-50) (-50) (-50) (-50) (-50) (-50) (-50) (-50) (-50) (-50) (-50)
				(-50) (-50) (-50) (-50) (-50) (-50) (-50) (-50) (-50) (-50) (-50) (-50) (-50) (-50) (-50) (-50) (-50) (-50)
				>;

			PS_Config_Diff_Test_Frame = <50>;

			PS_Config_Lmt_LPWG_Rawdata_P = <
				1689	1689	1696	1694	1677	1680	1674	1670	65535 65535	1689	1695	1685	1687	1692	1692	1691	1685
				1692	1682	1685	1677	1674	1681	1678	1673	1678	1684	1675	1673	1674	1678	1673	1685	1691	1680
				1689	1684	1677	1680	1688	1684	1681	1688	1698	1685	1680	1687	1689	1680	1681	1680	1674	1680
				1691	1703	1705	1681	1674	1675	1675	1675	1677	1689	1691	1691	1689	1695	1695	1691	1685	1688
				1687	1688	1681	1689	1691	1694	1699	1687	1695	1685	1685	1684	1684	1684	1680	1673	1696	1687
				1694	1685	1692	1687	1691	1691	1681	1689	1677	1689	1682	1681	1678	1680	1673	1678	1681	1687
				1681	1687	1682	1687	1675	1680	1682	1688	1685	1677	1680	1680	1681	1689	1677	1682	1678	1687
				1684	1687	1681	1691	1674	1680	1680	1687	1681	1678	1685	1684	1687	1685	1682	1675	1684	1687
				1684	1688	1684	1685	1692	1684	1687	1689	1691	1682	1678	1673	1671	1685	1684	1684	1684	1682
				1687	1692	1681	1685	1682	1682	1677	1678	1689	1666	1677	1666	1667	1691	1688	1687	1691	1687
				1680	1670	1675	1678	1688	1685	1687	1684	1678	1682	1678	1671	1677	1680	1692	1680	1694	1684
				1688	1671	1682	1681	1692	1685	1694	1685	1674	1663	1681	1678	1680	1684	1684	1684	1688	1694
				1687	1684	1684	1680	1684	1678	1684	1680	1677	1681	1685	1681	1677	1671	1688	1682	1685	1684
				1677	1688	1678	1688	1677	1684	1670	1682	1685	1675	1674	1675	1677	1682	1685	1681	1674	1675
				1681	1684	1687	1681	1674	1680	1687	1681	1685	1674	1673	1675	1685	1688	1675	1681	1684	1678
				1687	1684	1687	1688	1684	1681	1687	1682	1684	1677	1670	1671	1670	1682	1688	1673	1692	1682
				1685	1684	1680	1685	1674	1675	1681	1687	1677	1673	1674	1667	1661	1681	1687	1689	1675	1684
				1688	1685	1691	1680	1689	1681	1682	1680	1685	1688	1689	1692	1682	1687	1692	1682	1684	1689
				1673	1689	1677	1674	1677	1671	1675	1675	1682	1678	1682	1678	1677	1684	1684	1682	1684	1680
				1681	1682	1689	1689	1682	1681	1678	1681	1696	1689	1688	1684	1680	1687	1695	1680	1689	1680
				1681	1681	1688	1691	1677	1682	1684	1681	1691	1682	1678	1680	1681	1682	1685	1678	1677	1682
				1673	1680	1663	1680	1661	1671	1671	1667	1666	1688	1688	1682	1678	1681	1684	1681	1667	1695
				1675	1675	1684	1688	1682	1685	1687	1687	1687	1680	1682	1685	1677	1678	1678	1682	1666	1685
				1687	1692	1674	1678	1677	1682	1682	1681	1675	1691	1681	1685	1677	1685	1677	1681	1684	1685
				1675	1684	1666	1671	1681	1695	1691	1684	1677	1671	1668	1671	1666	1694	1674	1674	1675	1675
				1687	1681	1682	1684	1675	1675	1671	1678	1668	1673	1684	1681	1684	1685	1692	1675	1678	1684
				1682	1688	1684	1691	1677	1680	1681	1684	1689	1677	1677	1677	1682	1675	1678	1687	1685	1678
				1691	1675	1678	1677	1684	1680	1682	1681	1675	1680	1673	1673	1671	1682	1671	1674	1675	1694
				1675	1682	1675	1678	1691	1698	1687	1685	1688	1677	1681	1685	1682	1680	1675	1675	1688	1675
				1689	1680	1678	1680	1687	1694	1689	1682	1671	1682	1689	1691	1685	1663	1674	1674	1694	1684
				1680	1671	1689	1688	1692	1684	1698	1675	1661	1688	1681	1671	1674	1673	1668	1667	1678	1699
				1677	1688	1684	1688	1675	1685	1687	1688	1674	1680	1674	1674	1685	1682	1681	1680	1685	1673
				>;

			PS_Config_Lmt_LPWG_Rawdata_N = <
				724 724 727 726 718 720 717 715 (-65535) (-65535) 724 726 722 723 725 725 724 722
				725 721 722 718 717 720 719 717 719 721 718 717 717 719 717 722 724 720
				724 721 718 720 723 721 720 723 727 722 720 723 724 720 720 720 717 720
				724 730 730 720 717 718 718 718 718 724 724 724 724 726 726 724 722 723
				723 723 720 724 724 726 728 723 726 722 722 721 721 721 720 717 727 723
				726 722 725 723 724 724 720 724 718 724 721 720 719 720 717 719 720 723
				720 723 721 723 718 720 721 723 722 718 720 720 720 724 718 721 719 723
				721 723 720 724 717 720 720 723 720 719 722 721 723 722 721 718 721 723
				721 723 721 722 725 721 723 724 724 721 719 717 716 722 721 721 721 721
				723 725 720 722 721 721 718 719 724 714 718 714 714 724 723 723 724 723
				720 715 718 719 723 722 723 721 719 721 719 716 718 720 725 720 726 721
				723 716 721 720 725 722 726 722 717 712 720 719 720 721 721 721 723 726
				723 721 721 720 721 719 721 720 718 720 722 720 718 716 723 721 722 721
				718 723 719 723 718 721 715 721 722 718 717 718 718 721 722 720 717 718
				720 721 723 720 717 720 723 720 722 717 717 718 722 723 718 720 721 719
				723 721 723 723 721 720 723 721 721 718 715 716 715 721 723 717 725 721
				722 721 720 722 717 718 720 723 718 717 717 714 712 720 723 724 718 721
				723 722 724 720 724 720 721 720 722 723 724 725 721 723 725 721 721 724
				717 724 718 717 718 716 718 718 721 719 721 719 718 721 721 721 721 720
				720 721 724 724 721 720 719 720 727 724 723 721 720 723 726 720 724 720
				720 720 723 724 718 721 721 720 724 721 719 720 720 721 722 719 718 721
				717 720 712 720 712 716 716 714 714 723 723 721 719 720 721 720 714 726
				718 718 721 723 721 722 723 723 723 720 721 722 718 719 719 721 714 722
				723 725 717 719 718 721 721 720 718 724 720 722 718 722 718 720 721 722
				718 721 714 716 720 726 724 721 718 716 715 716 714 726 717 717 718 718
				723 720 721 721 718 718 716 719 715 717 721 720 721 722 725 718 719 721
				721 723 721 724 718 720 720 721 724 718 718 718 721 718 719 723 722 719
				724 718 719 718 721 720 721 720 718 720 717 717 716 721 716 717 718 726
				718 721 718 719 724 727 723 722 723 718 720 722 721 720 718 718 723 718
				724 720 719 720 723 726 724 721 716 721 724 724 722 712 717 717 726 721
				720 716 724 723 725 721 727 718 712 723 720 716 717 717 715 714 719 728
				718 723 721 723 718 722 723 723 717 720 717 717 722 721 720 720 722 717
				>;

			PS_Config_Lmt_LPWG_Diff_P = <
				60 60 60 60 60 60 60 60 65535 65535 60 60 60 60 60 60 60 60
				60 60 60 60 60 60 60 60 60 60 60 60 60 60 60 60 60 60
				60 60 60 60 60 60 60 60 60 60 60 60 60 60 60 60 60 60
				60 60 60 60 60 60 60 60 60 60 60 60 60 60 60 60 60 60
				60 60 60 60 60 60 60 60 60 60 60 60 60 60 60 60 60 60
				60 60 60 60 60 60 60 60 60 60 60 60 60 60 60 60 60 60
				60 60 60 60 60 60 60 60 60 60 60 60 60 60 60 60 60 60
				60 60 60 60 60 60 60 60 60 60 60 60 60 60 60 60 60 60
				60 60 60 60 60 60 60 60 60 60 60 60 60 60 60 60 60 60
				60 60 60 60 60 60 60 60 60 60 60 60 60 60 60 60 60 60
				60 60 60 60 60 60 60 60 60 60 60 60 60 60 60 60 60 60
				60 60 60 60 60 60 60 60 60 60 60 60 60 60 60 60 60 60
				60 60 60 60 60 60 60 60 60 60 60 60 60 60 60 60 60 60
				60 60 60 60 60 60 60 60 60 60 60 60 60 60 60 60 60 60
				60 60 60 60 60 60 60 60 60 60 60 60 60 60 60 60 60 60
				60 60 60 60 60 60 60 60 60 60 60 60 60 60 60 60 60 60
				60 60 60 60 60 60 60 60 60 60 60 60 60 60 60 60 60 60
				60 60 60 60 60 60 60 60 60 60 60 60 60 60 60 60 60 60
				60 60 60 60 60 60 60 60 60 60 60 60 60 60 60 60 60 60
				60 60 60 60 60 60 60 60 60 60 60 60 60 60 60 60 60 60
				60 60 60 60 60 60 60 60 60 60 60 60 60 60 60 60 60 60
				60 60 60 60 60 60 60 60 60 60 60 60 60 60 60 60 60 60
				60 60 60 60 60 60 60 60 60 60 60 60 60 60 60 60 60 60
				60 60 60 60 60 60 60 60 60 60 60 60 60 60 60 60 60 60
				60 60 60 60 60 60 60 60 60 60 60 60 60 60 60 60 60 60
				60 60 60 60 60 60 60 60 60 60 60 60 60 60 60 60 60 60
				60 60 60 60 60 60 60 60 60 60 60 60 60 60 60 60 60 60
				60 60 60 60 60 60 60 60 60 60 60 60 60 60 60 60 60 60
				60 60 60 60 60 60 60 60 60 60 60 60 60 60 60 60 60 60
				60 60 60 60 60 60 60 60 60 60 60 60 60 60 60 60 60 60
				60 60 60 60 60 60 60 60 60 60 60 60 60 60 60 60 60 60
				60 60 60 60 60 60 60 60 60 60 60 60 60 60 60 60 60 60
				>;

			PS_Config_Lmt_LPWG_Diff_N = <
				(-60)	(-60)	(-60)	(-60)	(-60)	(-60)	(-60)	(-60)	(-65535) (-65535) (-60) (-60) (-60) (-60) (-60) (-60) (-60) (-60)
				(-60)	(-60)	(-60)	(-60)	(-60)	(-60)	(-60)	(-60)	(-60)	(-60)	(-60)	(-60)	(-60)	(-60)	(-60)	(-60)	(-60)	(-60)
				(-60)	(-60)	(-60)	(-60)	(-60)	(-60)	(-60)	(-60)	(-60)	(-60)	(-60)	(-60)	(-60)	(-60)	(-60)	(-60)	(-60)	(-60)
				(-60)	(-60)	(-60)	(-60)	(-60)	(-60)	(-60)	(-60)	(-60)	(-60)	(-60)	(-60)	(-60)	(-60)	(-60)	(-60)	(-60)	(-60)
				(-60)	(-60)	(-60)	(-60)	(-60)	(-60)	(-60)	(-60)	(-60)	(-60)	(-60)	(-60)	(-60)	(-60)	(-60)	(-60)	(-60)	(-60)
				(-60)	(-60)	(-60)	(-60)	(-60)	(-60)	(-60)	(-60)	(-60)	(-60)	(-60)	(-60)	(-60)	(-60)	(-60)	(-60)	(-60)	(-60)
				(-60)	(-60)	(-60)	(-60)	(-60)	(-60)	(-60)	(-60)	(-60)	(-60)	(-60)	(-60)	(-60)	(-60)	(-60)	(-60)	(-60)	(-60)
				(-60)	(-60)	(-60)	(-60)	(-60)	(-60)	(-60)	(-60)	(-60)	(-60)	(-60)	(-60)	(-60)	(-60)	(-60)	(-60)	(-60)	(-60)
				(-60)	(-60)	(-60)	(-60)	(-60)	(-60)	(-60)	(-60)	(-60)	(-60)	(-60)	(-60)	(-60)	(-60)	(-60)	(-60)	(-60)	(-60)
				(-60)	(-60)	(-60)	(-60)	(-60)	(-60)	(-60)	(-60)	(-60)	(-60)	(-60)	(-60)	(-60)	(-60)	(-60)	(-60)	(-60)	(-60)
				(-60)	(-60)	(-60)	(-60)	(-60)	(-60)	(-60)	(-60)	(-60)	(-60)	(-60)	(-60)	(-60)	(-60)	(-60)	(-60)	(-60)	(-60)
				(-60)	(-60)	(-60)	(-60)	(-60)	(-60)	(-60)	(-60)	(-60)	(-60)	(-60)	(-60)	(-60)	(-60)	(-60)	(-60)	(-60)	(-60)
				(-60)	(-60)	(-60)	(-60)	(-60)	(-60)	(-60)	(-60)	(-60)	(-60)	(-60)	(-60)	(-60)	(-60)	(-60)	(-60)	(-60)	(-60)
				(-60)	(-60)	(-60)	(-60)	(-60)	(-60)	(-60)	(-60)	(-60)	(-60)	(-60)	(-60)	(-60)	(-60)	(-60)	(-60)	(-60)	(-60)
				(-60)	(-60)	(-60)	(-60)	(-60)	(-60)	(-60)	(-60)	(-60)	(-60)	(-60)	(-60)	(-60)	(-60)	(-60)	(-60)	(-60)	(-60)
				(-60)	(-60)	(-60)	(-60)	(-60)	(-60)	(-60)	(-60)	(-60)	(-60)	(-60)	(-60)	(-60)	(-60)	(-60)	(-60)	(-60)	(-60)
				(-60)	(-60)	(-60)	(-60)	(-60)	(-60)	(-60)	(-60)	(-60)	(-60)	(-60)	(-60)	(-60)	(-60)	(-60)	(-60)	(-60)	(-60)
				(-60)	(-60)	(-60)	(-60)	(-60)	(-60)	(-60)	(-60)	(-60)	(-60)	(-60)	(-60)	(-60)	(-60)	(-60)	(-60)	(-60)	(-60)
				(-60)	(-60)	(-60)	(-60)	(-60)	(-60)	(-60)	(-60)	(-60)	(-60)	(-60)	(-60)	(-60)	(-60)	(-60)	(-60)	(-60)	(-60)
				(-60)	(-60)	(-60)	(-60)	(-60)	(-60)	(-60)	(-60)	(-60)	(-60)	(-60)	(-60)	(-60)	(-60)	(-60)	(-60)	(-60)	(-60)
				(-60)	(-60)	(-60)	(-60)	(-60)	(-60)	(-60)	(-60)	(-60)	(-60)	(-60)	(-60)	(-60)	(-60)	(-60)	(-60)	(-60)	(-60)
				(-60)	(-60)	(-60)	(-60)	(-60)	(-60)	(-60)	(-60)	(-60)	(-60)	(-60)	(-60)	(-60)	(-60)	(-60)	(-60)	(-60)	(-60)
				(-60)	(-60)	(-60)	(-60)	(-60)	(-60)	(-60)	(-60)	(-60)	(-60)	(-60)	(-60)	(-60)	(-60)	(-60)	(-60)	(-60)	(-60)
				(-60)	(-60)	(-60)	(-60)	(-60)	(-60)	(-60)	(-60)	(-60)	(-60)	(-60)	(-60)	(-60)	(-60)	(-60)	(-60)	(-60)	(-60)
				(-60)	(-60)	(-60)	(-60)	(-60)	(-60)	(-60)	(-60)	(-60)	(-60)	(-60)	(-60)	(-60)	(-60)	(-60)	(-60)	(-60)	(-60)
				(-60)	(-60)	(-60)	(-60)	(-60)	(-60)	(-60)	(-60)	(-60)	(-60)	(-60)	(-60)	(-60)	(-60)	(-60)	(-60)	(-60)	(-60)
				(-60)	(-60)	(-60)	(-60)	(-60)	(-60)	(-60)	(-60)	(-60)	(-60)	(-60)	(-60)	(-60)	(-60)	(-60)	(-60)	(-60)	(-60)
				(-60)	(-60)	(-60)	(-60)	(-60)	(-60)	(-60)	(-60)	(-60)	(-60)	(-60)	(-60)	(-60)	(-60)	(-60)	(-60)	(-60)	(-60)
				(-60)	(-60)	(-60)	(-60)	(-60)	(-60)	(-60)	(-60)	(-60)	(-60)	(-60)	(-60)	(-60)	(-60)	(-60)	(-60)	(-60)	(-60)
				(-60)	(-60)	(-60)	(-60)	(-60)	(-60)	(-60)	(-60)	(-60)	(-60)	(-60)	(-60)	(-60)	(-60)	(-60)	(-60)	(-60)	(-60)
				(-60)	(-60)	(-60)	(-60)	(-60)	(-60)	(-60)	(-60)	(-60)	(-60)	(-60)	(-60)	(-60)	(-60)	(-60)	(-60)	(-60)	(-60)
				(-60)	(-60)	(-60)	(-60)	(-60)	(-60)	(-60)	(-60)	(-60)	(-60)	(-60)	(-60)	(-60)	(-60)	(-60)	(-60)	(-60)	(-60)
				>;
		}; /* novatek-mp-criteria-hlt */
	};
};
/*Yuexiu.Wu@ODM_WT.WCN.NFC.Basic.1941873,2019/5/12,add for P73 driver*/
&qupv3_se0_spi {
	status = "ok";
	p61@0 {
		compatible = "nxp,p61";
		reg = <0>; //Same as CS ID
		spi-max-frequency = <9600000>;	//4800000,9600000,15000000,19200000
	};
};
&sdhc_1 {
	vdd-supply = <&pm6125_l24>;
	qcom,vdd-voltage-level = <2950000 2950000>;
	qcom,vdd-current-level = <0 570000>;

	vdd-io-supply = <&pm6125_l11>;
	qcom,vdd-io-always-on;
	qcom,vdd-io-lpm-sup;
	qcom,vdd-io-voltage-level = <1800000 1800000>;
	qcom,vdd-io-current-level = <0 325000>;

	pinctrl-names = "active", "sleep";
	pinctrl-0 = <&sdc1_clk_on &sdc1_cmd_on &sdc1_data_on
					&sdc1_rclk_on>;
	pinctrl-1 = <&sdc1_clk_off &sdc1_cmd_off &sdc1_data_off
					&sdc1_rclk_off>;

	status = "ok";
};

&sdhc_2 {
	vdd-supply = <&pm6125_l22>;
	qcom,vdd-voltage-level = <2950000 2950000>;
	qcom,vdd-current-level = <0 800000>;

	vdd-io-supply = <&pm6125_l5>;
	qcom,vdd-io-voltage-level = <1800000 2950000>;
	qcom,vdd-io-current-level = <0 22000>;

	pinctrl-names = "active", "sleep";
	pinctrl-0 = <&sdc2_clk_on  &sdc2_cmd_on &sdc2_data_on &sdc2_cd_on>;
	pinctrl-1 = <&sdc2_clk_off &sdc2_cmd_off &sdc2_data_off &sdc2_cd_off>;

	//#ifdef ODM_WT_EDIT
        //Haibin1.Zhang@ODM_WT.BSP.Storage.sdcard, 2019/04/25, Modify for SDcard configuration
	cd-gpios = <&tlmm 98 GPIO_ACTIVE_HIGH>;
	//#endif

	status = "ok";
};

&pmi632_qg {
//#ifndef ODM_WT_EDIT
/* Bin2.Zhang@ODM_WT.BSP.Charger.Basic.1941873, 20190429, Add for change charger behavior */
//	qcom,battery-data = <&mtp_batterydata>;
//	qcom,qg-iterm-ma = <100>;
//	qcom,hold-soc-while-full;
//	qcom,linearize-soc;
//	qcom,qg-use-s7-ocv;
//#else /* ODM_WT_EDIT */
	qcom,battery-data = <&mtp_batterydata>;
	qcom,qg-iterm-ma = <350>;
	qcom,hold-soc-while-full;
	qcom,linearize-soc;
	qcom,qg-use-s7-ocv;
	qcom,s3-entry-ibat-ua = <18000>;
	qcom,s3-exit-ibat-ua = <38000>;

	qcom,qg-restore-batt-info;
//#endif /* ODM_WT_EDIT */
};

&pmi632_charger {
//#ifndef ODM_WT_EDIT
/* Bin2.Zhang@ODM_WT.BSP.Charger.Basic.1941873, 20190429, Add for change charger behavior */
//	qcom,battery-data = <&mtp_batterydata>;
//	qcom,suspend-input-on-debug-batt;
//	qcom,sw-jeita-enable;
//	qcom,step-charging-enable;
//	/* SMB1355 only */
//	qcom,sec-charger-config = <2>;
//	dpdm-supply = <&qusb_phy0>;
//	qcom,charger-temp-max = <800>;
//	qcom,smb-temp-max = <800>;
//	qcom,auto-recharge-soc = <98>;
//	qcom,flash-disable-soc = <10>;
//	qcom,hw-die-temp-mitigation;
//	qcom,hw-connector-mitigation;
//	qcom,connector-internal-pull-kohm = <100>;
//	qcom,thermal-mitigation = <3000000 2500000
//			2000000 1500000 1000000 500000>;
//#else /* ODM_WT_EDIT */
/* Bin2.Zhang@ODM_WT.BSP.Charger.Basic.1941873, 20190429, Add for change charger behavior */
	qcom,battery-data = <&mtp_batterydata>;
	qcom,suspend-input-on-debug-batt;
	dpdm-supply = <&qusb_phy0>;
	//#ifdef ODM_WT_EDIT
	/*dijin.liu@Cam.Drv , 2074359 , remove platform setting under lower power mode can not use flash */
	/* 10 -> 0 */
	qcom,flash-disable-soc = <0>;
	//#endif
	qcom,thermal-mitigation = <3000000 2500000
			2000000 1500000 1000000 500000>;

	qcom,usb-icl-ua = <2000000>;
	qcom,auto-recharge-vbat-mv = <4270>;
	//qcom,sw-jeita-enable;
	qcom,float-option = <1>;
	qcom,hvdcp-disable;
//#endif /* ODM_WT_EDIT */
};

&usb0 {
	extcon = <&pmi632_charger>, <&eud>;
};

&pmi632_gpios {
	smb_en {
		smb_en_default: smb_en_default {
			pins = "gpio2";
			function = "func1";
			output-enable;
		};
	};

	pmi632_sense {
		/* GPIO 7 and 8 are external-sense pins for PMI632 */
		pmi632_sense_default: pmi632_sense_default {
			pins = "gpio7", "gpio8";
			bias-high-impedance;	/* disable the GPIO */
			bias-disable;		/* no-pull */
		};
	};

	pmi632_ctm {
		/* Disable GPIO1 for h/w base mitigation */
		pmi632_ctm_default: pmi632_ctm_default {
			pins = "gpio1";
			bias-high-impedance;	/* disable the GPIO */
			bias-disable;		/* no-pull */
		};
	};
};

&pm6125_gpios {
	key_vol_up {
		key_vol_up_default: key_vol_up_default {
			pins = "gpio5";
			function = "normal";
			input-enable;
			bias-pull-up;
			power-source = <0>;
		};
	};
};

&soc {
	gpio_keys {
		compatible = "gpio-keys";
		label = "gpio-keys";

		pinctrl-names = "default";
		pinctrl-0 = <&key_vol_up_default>;
		//Gong.Chen@ODM_WT.Bsp.Key.Function.1941873, 2019/04/10, Modify for keyfunction
		vol_up {
			label = "volume-down";
			gpios = <&pm6125_gpios 5 GPIO_ACTIVE_LOW>;
			linux,input-type = <1>;
			linux,code = <KEY_VOLUMEDOWN>;
			linux,can-disable;
			debounce-interval = <15>;
			gpio-key,wakeup;
		};
	};
};

//Gong.Chen@ODM_WT.Bsp.Key.Function.1941873, 2019/04/10, Add for keyfunction
&spmi_bus {
	qcom,pm6125@0 {
		qcom,power-on@800 {
			qcom,pon_2 {
				qcom,pon-type = <PON_POWER_ON_TYPE_RESIN>;
				qcom,pull-up = <1>;
				linux,code = <KEY_VOLUMEUP>;
			};
		};
	};
};

&tlmm {
	smb_int_default: smb_int_default {
		mux {
			pins = "gpio130";
			function = "gpio";
		};
		config {
			pins = "gpio130";
			bias-pull-up;
			input-enable;
		};
	};
};

&smb1355 {
	pinctrl-names = "default";
	pinctrl-0 = <&smb_int_default>;
	interrupt-parent = <&tlmm>;
	interrupts = <130 IRQ_TYPE_LEVEL_LOW>;
	status = "ok";
};

&smb1355_charger {
	pinctrl-names = "default";
	pinctrl-0 = <&smb_en_default &pmi632_sense_default &pmi632_ctm_default>;
	qcom,parallel-mode = <1>;
	qcom,disable-ctm;
	qcom,hw-die-temp-mitigation;
	status = "ok";
};

&ufsphy_mem {
	compatible = "qcom,ufs-phy-qmp-v3-660";

	vdda-phy-supply = <&pm6125_l4>; /* 0.9v */
	vdda-pll-supply = <&pm6125_l10>; /* 1.8v */
	vdda-phy-max-microamp = <51400>;
	vdda-pll-max-microamp = <14200>;

	status = "ok";
};

&ufshc_mem {
	vdd-hba-supply = <&ufs_phy_gdsc>;
	vdd-hba-fixed-regulator;
	vcc-supply = <&pm6125_l24>;
	vcc-voltage-level = <2950000 2960000>;
	vccq2-supply = <&pm6125_l11>;
	vcc-max-microamp = <600000>;
	vccq2-max-microamp = <600000>;

	qcom,vddp-ref-clk-supply = <&pm6125_l18>;
	qcom,vddp-ref-clk-max-microamp = <100>;
	qcom,vddp-ref-clk-min-uV = <1200000>;
	qcom,vddp-ref-clk-max-uV = <1232000>;

	status = "ok";
};

&pm6125_pwm {
	status = "ok";
};

&dsi_td4330_truly_video {
	qcom,panel-supply-entries = <&dsi_panel_pwr_supply>;
	qcom,mdss-dsi-bl-pmic-control-type = "bl_ctrl_pwm";
	pwms = <&pm6125_pwm 0 0>;
	qcom,bl-pmic-pwm-period-usecs = <100>;
	qcom,mdss-dsi-bl-min-level = <1>;
	qcom,mdss-dsi-bl-max-level = <4095>;
	qcom,platform-reset-gpio = <&tlmm 90 0>;
	qcom,platform-bklight-en-gpio = <&pmi632_gpios 6 0>;
};

&dsi_td4330_truly_cmd {
	qcom,panel-supply-entries = <&dsi_panel_pwr_supply>;
	qcom,mdss-dsi-bl-pmic-control-type = "bl_ctrl_pwm";
	pwms = <&pm6125_pwm 0 0>;
	qcom,bl-pmic-pwm-period-usecs = <100>;
	qcom,mdss-dsi-bl-min-level = <1>;
	qcom,mdss-dsi-bl-max-level = <4095>;
	qcom,platform-te-gpio = <&tlmm 89 0>;
	qcom,platform-reset-gpio = <&tlmm 90 0>;
	qcom,platform-bklight-en-gpio = <&pmi632_gpios 6 0>;
};

&dsi_sim_vid {
	qcom,panel-supply-entries = <&dsi_panel_pwr_supply>;
	qcom,mdss-dsi-bl-pmic-control-type = "bl_ctrl_dcs";
	qcom,platform-reset-gpio = <&tlmm 90 0>;
};

&dsi_hx83112a_truly_video {
	qcom,panel-supply-entries = <&dsi_panel_pwr_supply>;
	qcom,mdss-dsi-bl-pmic-control-type = "bl_ctrl_pwm";
	pwms = <&pm6125_pwm 0 0>;
	qcom,bl-pmic-pwm-period-usecs = <100>;
	qcom,mdss-dsi-bl-min-level = <1>;
	qcom,mdss-dsi-bl-max-level = <4095>;
	qcom,platform-reset-gpio = <&tlmm 90 0>;
	qcom,platform-bklight-en-gpio = <&pmi632_gpios 6 0>;
};

&dsi_nt36672_truly_video {
	qcom,panel-supply-entries = <&dsi_panel_pwr_supply>;
	qcom,mdss-dsi-bl-pmic-control-type = "bl_ctrl_pwm";
	pwms = <&pm6125_pwm 0 0>;
	qcom,bl-pmic-pwm-period-usecs = <100>;
	qcom,mdss-dsi-bl-min-level = <1>;
	qcom,mdss-dsi-bl-max-level = <4095>;
	qcom,platform-reset-gpio = <&tlmm 90 0>;
	qcom,platform-bklight-en-gpio = <&pmi632_gpios 6 0>;
};

//#ifdef ODM_WT_EDIT
//Hongzhu.Su@ODM_WT.MM.Display.Lcd.1941873, Start 2019/04/6, Add for LCD bring up
&dsi_ili9881h_truly_video {
	qcom,panel-supply-entries = <&dsi_panel_pwr_supply>;
	qcom,platform-reset-gpio = <&tlmm 90 0>;
};
&dsi_ili9881h_truly_video_display {
	qcom,dsi-display-active;
};

&dsi_hx83102d_auo_video {
	qcom,panel-supply-entries = <&dsi_panel_pwr_supply>;
	qcom,platform-reset-gpio = <&tlmm 90 0>;
};
&dsi_hx83102d_auo_video_display {
	qcom,dsi-display-active;
};

&dsi_ili9881h_truly_auo_video {
	qcom,panel-supply-entries = <&dsi_panel_pwr_supply>;
	qcom,platform-reset-gpio = <&tlmm 90 0>;
};
&dsi_ili9881h_truly_auo_video_display {
	qcom,dsi-display-active;
};

&dsi_ili9881h_innolux_inx_video {
	qcom,panel-supply-entries = <&dsi_panel_pwr_supply>;
	qcom,platform-reset-gpio = <&tlmm 90 0>;
};
&dsi_ili9881h_innolux_inx_video_display {
	qcom,dsi-display-active;
};

&dsi_nt36525b_hlt_boe_video {
	qcom,panel-supply-entries = <&dsi_panel_pwr_supply>;
	qcom,platform-reset-gpio = <&tlmm 90 0>;
};
&dsi_nt36525b_hlt_boe_video_display {
	qcom,dsi-display-active;
};
//Hongzhu.Su@ODM_WT.MM.Display.Lcd.1941873, End 2019/04/6, Add for LCD bring up
//#endif /* ODM_WT_EDIT */

&qupv3_se2_i2c {
	status = "okay";
	qcom,i2c-touch-active="synaptics,tcm-i2c";

	synaptics_tcm@20 {
		compatible = "synaptics,tcm-i2c";
		reg = <0x20>;
		interrupt-parent = <&tlmm>;
		interrupts = <88 0x2008>;
		pinctrl-names = "pmx_ts_active","pmx_ts_suspend",
					"pmx_ts_release";
		pinctrl-0 = <&ts_int_active &ts_reset_active>;
		pinctrl-1 = <&ts_int_suspend &ts_reset_suspend>;
		pinctrl-2 = <&ts_release>;
		synaptics,irq-gpio = <&tlmm 88 0x2008>;
		synaptics,irq-on-state = <0>;
		synaptics,reset-gpio = <&tlmm 87 0x00>;
		synaptics,reset-on-state = <0>;
		synaptics,reset-active-ms = <20>;
		synaptics,reset-delay-ms = <200>;
		synaptics,power-delay-ms = <200>;
		synaptics,ubl-i2c-addr = <0x20>;
		synaptics,y-flip;
	};

	himax_ts@48 {
		compatible = "himax,hxcommon";
		reg = <0x48>;
		interrupt-parent = <&tlmm>;
		interrupts = <88 0x2008>;
		pinctrl-names = "pmx_ts_active","pmx_ts_suspend",
			"pmx_ts_release";
		pinctrl-0 = <&ts_int_active &ts_reset_active>;
		pinctrl-1 = <&ts_int_suspend &ts_reset_suspend>;
		pinctrl-2 = <&ts_release>;
		himax,panel-coords = <0 1080 0 2160>;
		himax,display-coords = <0 1080 0 2160>;
		himax,irq-gpio = <&tlmm 88 0x00>;
		himax,rst-gpio = <&tlmm 87 0x00>;
		report_type = <1>;
	};
};

